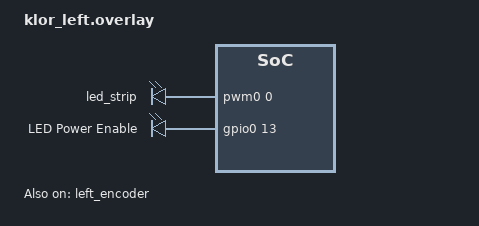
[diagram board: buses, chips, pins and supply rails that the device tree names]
/*
 * Copyright (c) 2022 GEIST
 *
 * SPDX-License-Identifier: MIT
 */

#include "klor.dtsi"

&kscan0 {
    col-gpios
        = <&pro_micro 19 GPIO_ACTIVE_HIGH>
        , <&pro_micro 18 GPIO_ACTIVE_HIGH>
        , <&pro_micro 15 GPIO_ACTIVE_HIGH>
        , <&pro_micro 14 GPIO_ACTIVE_HIGH>
        , <&pro_micro 16 GPIO_ACTIVE_HIGH>
        , <&pro_micro 10 GPIO_ACTIVE_HIGH>
        ;
};

&left_encoder {
    status = "okay";
};

/ {

    leds {
        compatible = "pwm-leds";
        led_strip: led_strip {
            pwms = <&pwm0 0 PWM_MSEC(20) PWM_POLARITY_NORMAL>;
            chain-length = <21>;
          };
    };
};

/ {
    leds {
        compatible = "gpio-leds";
        led_power: led_power {
            gpios = <&gpio0 13 GPIO_ACTIVE_HIGH>; // P0.13 as GPIO output
            label = "LED Power Enable";
        };
    };
};
